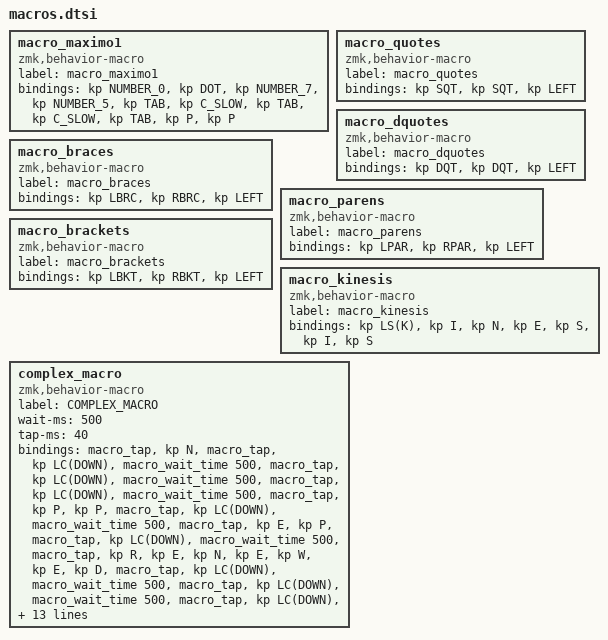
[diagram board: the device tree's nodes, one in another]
macro_maximo1: macro_maximo1{
compatible = "zmk,behavior-macro";
label = "macro_maximo1";
#binding-cells = <0>;
bindings = <&kp NUMBER_0>, <&kp DOT>, <&kp NUMBER_7>, <&kp NUMBER_5>, <&kp TAB>, <&kp C_SLOW>, <&kp TAB>, <&kp C_SLOW>, <&kp TAB>, <&kp P>, <&kp P>;
};
macro_quotes: macro_quotes{
compatible = "zmk,behavior-macro";
label = "macro_quotes";
#binding-cells = <0>;
bindings = <&kp SQT>, <&kp SQT>, <&kp LEFT>;
};
macro_dquotes: macro_dquotes{
compatible = "zmk,behavior-macro";
label = "macro_dquotes";
#binding-cells = <0>;
bindings = <&kp DQT>, <&kp DQT>, <&kp LEFT>;
};
macro_braces: macro_braces{
compatible = "zmk,behavior-macro";
label = "macro_braces";
#binding-cells = <0>;
bindings = <&kp LBRC>, <&kp RBRC>, <&kp LEFT>;
};
macro_parens: macro_parens{
compatible = "zmk,behavior-macro";
label = "macro_parens";
#binding-cells = <0>;
bindings = <&kp LPAR>, <&kp RPAR>, <&kp LEFT>;
};
macro_brackets: macro_brackets{
compatible = "zmk,behavior-macro";
label = "macro_brackets";
#binding-cells = <0>;
bindings = <&kp LBKT>, <&kp RBKT>, <&kp LEFT>;
};
macro_kinesis: macro_kinesis{
compatible = "zmk,behavior-macro";
label = "macro_kinesis";
#binding-cells = <0>;
bindings = <&kp LS(K)>, <&kp I>, <&kp N>, <&kp E>, <&kp S>, <&kp I>, <&kp S>;
};
complex_macro: complex_macro {
    label = "COMPLEX_MACRO";
    compatible = "zmk,behavior-macro";
    #binding-cells = <0>;
    wait-ms = <500>;
    tap-ms = <40>;
    bindings
        = <&macro_tap &kp N>
        , <&macro_tap &kp LC(DOWN)>
        , <&macro_wait_time 500>
        , <&macro_tap &kp LC(DOWN)>
        , <&macro_wait_time 500>
        , <&macro_tap &kp LC(DOWN)>
        , <&macro_wait_time 500>
        , <&macro_tap &kp P &kp P>
        , <&macro_tap &kp LC(DOWN)>
        , <&macro_wait_time 500>
        , <&macro_tap &kp E &kp P>
        , <&macro_tap &kp LC(DOWN)>
        , <&macro_wait_time 500>
        , <&macro_tap &kp R &kp E &kp N &kp E &kp W &kp E &kp D>
        , <&macro_tap &kp LC(DOWN)>
        , <&macro_wait_time 500>
        , <&macro_tap &kp LC(DOWN)>
        , <&macro_wait_time 500>
        , <&macro_tap &kp LC(DOWN)>
        , <&macro_wait_time 500>
        , <&macro_tap &kp LC(DOWN)>
        , <&macro_wait_time 500>
        , <&macro_tap &kp LC(DOWN)>
        , <&macro_wait_time 500>
        , <&macro_tap &kp LC(DOWN)>
        , <&macro_wait_time 500>
        , <&macro_tap &kp N0>
        , <&macro_tap &kp LC(DOWN)>
        , <&macro_wait_time 500>
        , <&macro_tap &kp V &kp I &kp S &kp U &kp A &kp L>
        , <&macro_tap &kp LC(DOWN)>
        , <&macro_wait_time 500>
        , <&macro_tap &kp E &kp L &kp E &kp C &kp T &kp R &kp O>
        , <&macro_tap &kp LC(DOWN)>
        , <&macro_wait_time 500>
        , <&macro_tap &kp LC(DOWN)>
        , <&macro_wait_time 500>
        , <&macro_tap &kp LC(DOWN)>
        , <&macro_wait_time 500>
        , <&macro_tap &kp N &kp FSLH &kp A>
        ;
};
